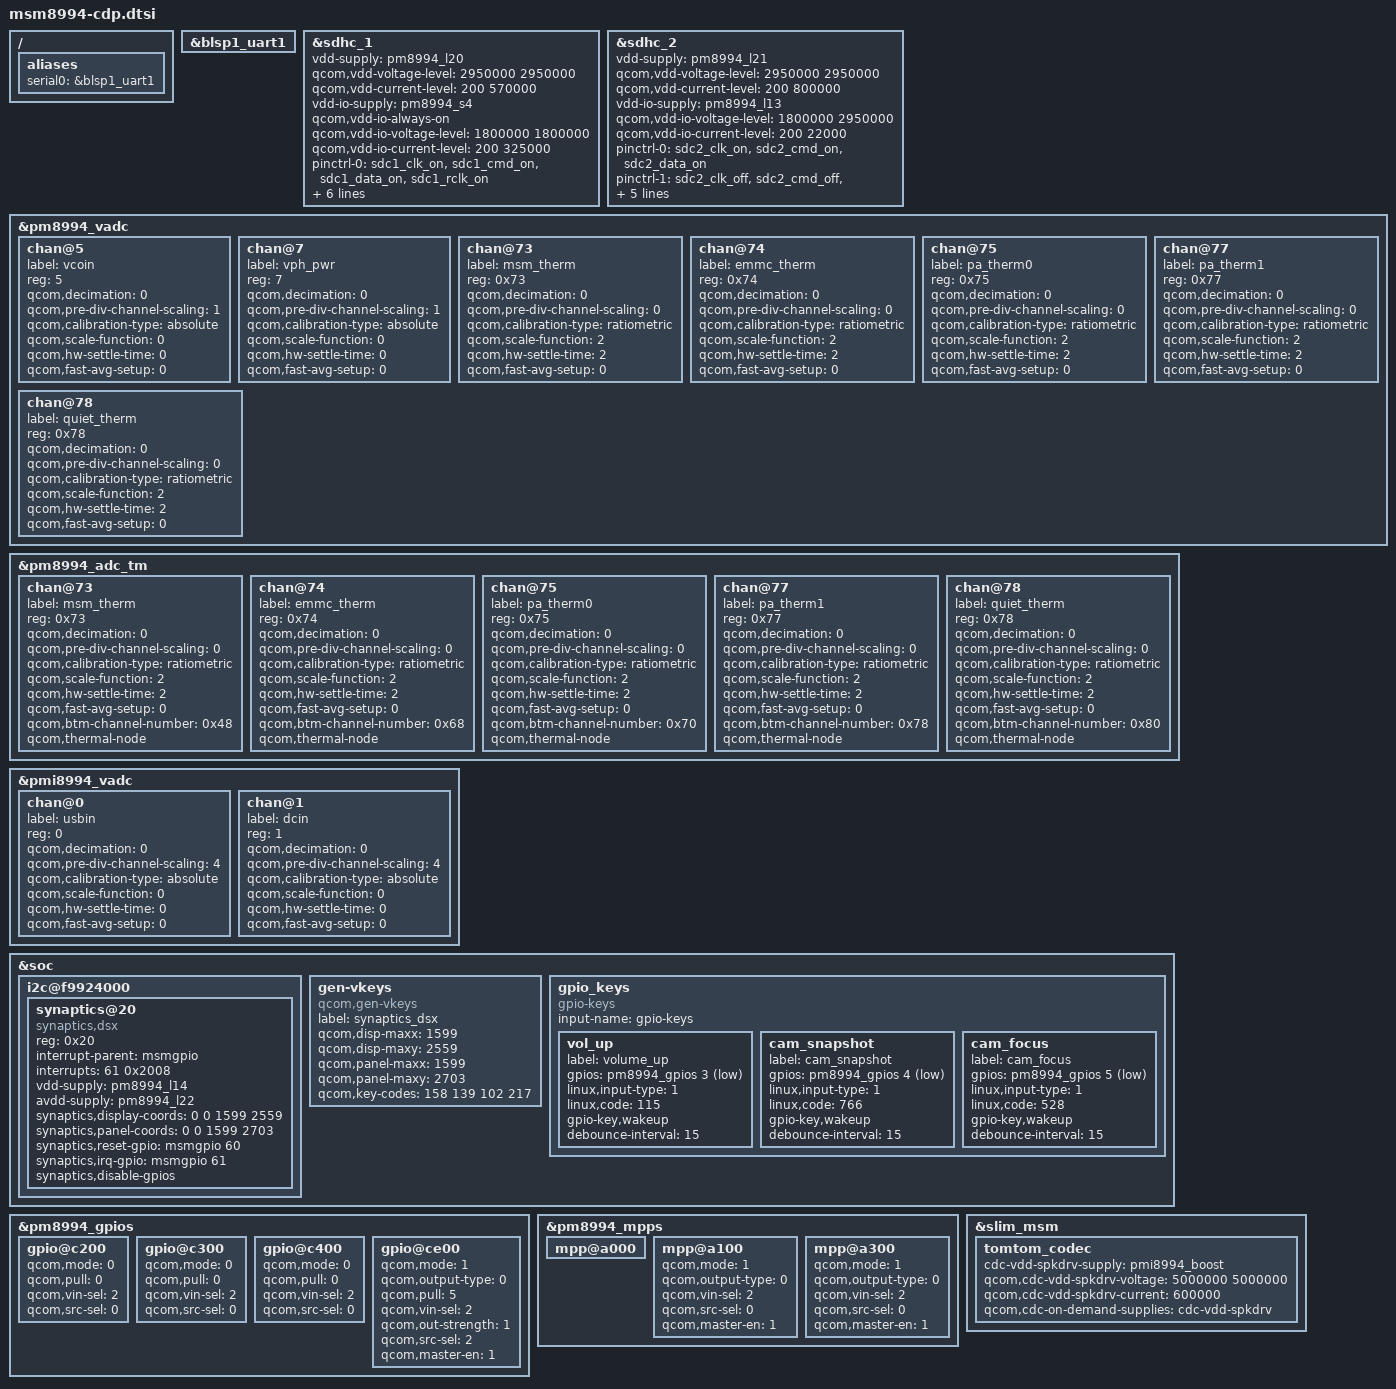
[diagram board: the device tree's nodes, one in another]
/* Copyright (c) 2014, The Linux Foundation. All rights reserved.
 *
 * This program is free software; you can redistribute it and/or modify
 * it under the terms of the GNU General Public License version 2 and
 * only version 2 as published by the Free Software Foundation.
 *
 * This program is distributed in the hope that it will be useful,
 * but WITHOUT ANY WARRANTY; without even the implied warranty of
 * MERCHANTABILITY or FITNESS FOR A PARTICULAR PURPOSE.  See the
 * GNU General Public License for more details.
 */

/ {
	aliases {
		serial0 = &blsp1_uart1;
	};
};

&blsp1_uart1{
	status = "ok";
};

&sdhc_1 {
	vdd-supply = <&pm8994_l20>;
	qcom,vdd-voltage-level = <2950000 2950000>;
	qcom,vdd-current-level = <200 570000>;

	vdd-io-supply = <&pm8994_s4>;
	qcom,vdd-io-always-on;
	qcom,vdd-io-voltage-level = <1800000 1800000>;
	qcom,vdd-io-current-level = <200 325000>;

	pinctrl-names = "active", "sleep";
	pinctrl-0 = <&sdc1_clk_on &sdc1_cmd_on &sdc1_data_on &sdc1_rclk_on>;
	pinctrl-1 = <&sdc1_clk_off &sdc1_cmd_off &sdc1_data_off &sdc1_rclk_off>;

	qcom,nonremovable;

	qcom,clk-rates = <400000 20000000 25000000 50000000 100000000 192000000>;
	qcom,bus-speed-mode = "HS200_1p8v", "DDR_1p8v";
	status = "ok";
};

&sdhc_2 {
	vdd-supply = <&pm8994_l21>;
	qcom,vdd-voltage-level = <2950000 2950000>;
	qcom,vdd-current-level = <200 800000>;

	vdd-io-supply = <&pm8994_l13>;
	qcom,vdd-io-voltage-level = <1800000 2950000>;
	qcom,vdd-io-current-level = <200 22000>;

	pinctrl-names = "active", "sleep";
	pinctrl-0 = <&sdc2_clk_on &sdc2_cmd_on &sdc2_data_on>;
	pinctrl-1 = <&sdc2_clk_off &sdc2_cmd_off &sdc2_data_off>;

	qcom,clk-rates = <400000 20000000 25000000 50000000 100000000 200000000>;
	qcom,bus-speed-mode = "SDR12", "SDR25", "SDR50", "DDR50", "SDR104";
	status = "ok";
};

&pm8994_vadc {
	chan@5 {
		label = "vcoin";
		reg = <5>;
		qcom,decimation = <0>;
		qcom,pre-div-channel-scaling = <1>;
		qcom,calibration-type = "absolute";
		qcom,scale-function = <0>;
		qcom,hw-settle-time = <0>;
		qcom,fast-avg-setup = <0>;
	};

	chan@7 {
		label = "vph_pwr";
		reg = <7>;
		qcom,decimation = <0>;
		qcom,pre-div-channel-scaling = <1>;
		qcom,calibration-type = "absolute";
		qcom,scale-function = <0>;
		qcom,hw-settle-time = <0>;
		qcom,fast-avg-setup = <0>;
	};

	chan@73 {
		label = "msm_therm";
		reg = <0x73>;
		qcom,decimation = <0>;
		qcom,pre-div-channel-scaling = <0>;
		qcom,calibration-type = "ratiometric";
		qcom,scale-function = <2>;
		qcom,hw-settle-time = <2>;
		qcom,fast-avg-setup = <0>;
	};

	chan@74 {
		label = "emmc_therm";
		reg = <0x74>;
		qcom,decimation = <0>;
		qcom,pre-div-channel-scaling = <0>;
		qcom,calibration-type = "ratiometric";
		qcom,scale-function = <2>;
		qcom,hw-settle-time = <2>;
		qcom,fast-avg-setup = <0>;
	};

	chan@75 {
		label = "pa_therm0";
		reg = <0x75>;
		qcom,decimation = <0>;
		qcom,pre-div-channel-scaling = <0>;
		qcom,calibration-type = "ratiometric";
		qcom,scale-function = <2>;
		qcom,hw-settle-time = <2>;
		qcom,fast-avg-setup = <0>;
	};

	chan@77 {
		label = "pa_therm1";
		reg = <0x77>;
		qcom,decimation = <0>;
		qcom,pre-div-channel-scaling = <0>;
		qcom,calibration-type = "ratiometric";
		qcom,scale-function = <2>;
		qcom,hw-settle-time = <2>;
		qcom,fast-avg-setup = <0>;
	};

	chan@78 {
		label = "quiet_therm";
		reg = <0x78>;
		qcom,decimation = <0>;
		qcom,pre-div-channel-scaling = <0>;
		qcom,calibration-type = "ratiometric";
		qcom,scale-function = <2>;
		qcom,hw-settle-time = <2>;
		qcom,fast-avg-setup = <0>;
	};
};

&pm8994_adc_tm {
	chan@73 {
		label = "msm_therm";
		reg = <0x73>;
		qcom,decimation = <0>;
		qcom,pre-div-channel-scaling = <0>;
		qcom,calibration-type = "ratiometric";
		qcom,scale-function = <2>;
		qcom,hw-settle-time = <2>;
		qcom,fast-avg-setup = <0>;
		qcom,btm-channel-number = <0x48>;
		qcom,thermal-node;
	};

	chan@74 {
		label = "emmc_therm";
		reg = <0x74>;
		qcom,decimation = <0>;
		qcom,pre-div-channel-scaling = <0>;
		qcom,calibration-type = "ratiometric";
		qcom,scale-function = <2>;
		qcom,hw-settle-time = <2>;
		qcom,fast-avg-setup = <0>;
		qcom,btm-channel-number = <0x68>;
		qcom,thermal-node;
	};

	chan@75 {
		label = "pa_therm0";
		reg = <0x75>;
		qcom,decimation = <0>;
		qcom,pre-div-channel-scaling = <0>;
		qcom,calibration-type = "ratiometric";
		qcom,scale-function = <2>;
		qcom,hw-settle-time = <2>;
		qcom,fast-avg-setup = <0>;
		qcom,btm-channel-number = <0x70>;
		qcom,thermal-node;
	};

	chan@77 {
		label = "pa_therm1";
		reg = <0x77>;
		qcom,decimation = <0>;
		qcom,pre-div-channel-scaling = <0>;
		qcom,calibration-type = "ratiometric";
		qcom,scale-function = <2>;
		qcom,hw-settle-time = <2>;
		qcom,fast-avg-setup = <0>;
		qcom,btm-channel-number = <0x78>;
		qcom,thermal-node;
	};

	chan@78 {
		label = "quiet_therm";
		reg = <0x78>;
		qcom,decimation = <0>;
		qcom,pre-div-channel-scaling = <0>;
		qcom,calibration-type = "ratiometric";
		qcom,scale-function = <2>;
		qcom,hw-settle-time = <2>;
		qcom,fast-avg-setup = <0>;
		qcom,btm-channel-number = <0x80>;
		qcom,thermal-node;
	};
};

&pmi8994_vadc {
	chan@0 {
		label = "usbin";
		reg = <0>;
		qcom,decimation = <0>;
		qcom,pre-div-channel-scaling = <4>;
		qcom,calibration-type = "absolute";
		qcom,scale-function = <0>;
		qcom,hw-settle-time = <0>;
		qcom,fast-avg-setup = <0>;
	};

	chan@1 {
		label = "dcin";
		reg = <1>;
		qcom,decimation = <0>;
		qcom,pre-div-channel-scaling = <4>;
		qcom,calibration-type = "absolute";
		qcom,scale-function = <0>;
		qcom,hw-settle-time = <0>;
		qcom,fast-avg-setup = <0>;
	};
};

&soc {
	i2c@f9924000 {
		synaptics@20 {
			compatible = "synaptics,dsx";
			reg = <0x20>;
			interrupt-parent = <&msmgpio>;
			interrupts = <61 0x2008>;
			vdd-supply = <&pm8994_l14>;
			avdd-supply = <&pm8994_l22>;
			synaptics,display-coords = <0 0 1599 2559>;
			synaptics,panel-coords = <0 0 1599 2703>;
			synaptics,reset-gpio = <&msmgpio 60 0x00>;
			synaptics,irq-gpio = <&msmgpio 61 0x2008>;
			synaptics,disable-gpios;
		};
	};

	gen-vkeys {
		compatible = "qcom,gen-vkeys";
		label = "synaptics_dsx";
		qcom,disp-maxx = <1599>;
		qcom,disp-maxy = <2559>;
		qcom,panel-maxx = <1599>;
		qcom,panel-maxy = <2703>;
		qcom,key-codes = <158 139 102 217>;
	};

	gpio_keys {
		compatible = "gpio-keys";
		input-name = "gpio-keys";

		vol_up {
			label = "volume_up";
			gpios = <&pm8994_gpios 3 0x1>;
			linux,input-type = <1>;
			linux,code = <115>;
			gpio-key,wakeup;
			debounce-interval = <15>;
		};

		cam_snapshot {
			label = "cam_snapshot";
			gpios = <&pm8994_gpios 4 0x1>;
			linux,input-type = <1>;
			linux,code = <766>;
			gpio-key,wakeup;
			debounce-interval = <15>;
		};

		cam_focus {
			label = "cam_focus";
			gpios = <&pm8994_gpios 5 0x1>;
			linux,input-type = <1>;
			linux,code = <528>;
			gpio-key,wakeup;
			debounce-interval = <15>;
		};


	};
};

&pm8994_gpios {
	gpio@c200 { /* GPIO 3 */
		qcom,mode = <0>;
		qcom,pull = <0>;
		qcom,vin-sel = <2>;
		qcom,src-sel = <0>;
	};

	gpio@c300 { /* GPIO 4 */
		qcom,mode = <0>;
		qcom,pull = <0>;
		qcom,vin-sel = <2>;
		qcom,src-sel = <0>;
	};

	gpio@c400 { /* GPIO 5 */
		qcom,mode = <0>;
		qcom,pull = <0>;
		qcom,vin-sel = <2>;
		qcom,src-sel = <0>;
	};

	gpio@ce00 { /* GPIO 15 */
		qcom,mode = <1>;
		qcom,output-type = <0>;
		qcom,pull = <5>;
		qcom,vin-sel = <2>;
		qcom,out-strength = <1>;
		qcom,src-sel = <2>;
		qcom,master-en = <1>;
	};
};

&pm8994_mpps {
	mpp@a000 { /* MPP 1 */
	};

	mpp@a100 { /* MPP 2 */
		qcom,mode = <1>;		/* Digital output */
		qcom,output-type = <0>;		/* CMOS logic */
		qcom,vin-sel = <2>;		/* S4 1.8V */
		qcom,src-sel = <0>;		/* Constant */
		qcom,master-en = <1>;		/* Enable GPIO */
	};

	mpp@a300 { /* MPP 4 */
		/* HDMI_5v_vreg regulator enable */
		qcom,mode = <1>;		/* Digital output */
		qcom,output-type = <0>;		/* CMOS logic */
		qcom,vin-sel = <2>;		/* S4 1.8V */
		qcom,src-sel = <0>;		/* Constant */
		qcom,master-en = <1>;		/* Enable GPIO */
	};
};

&slim_msm {
	tomtom_codec {
		cdc-vdd-spkdrv-supply = <&pmi8994_boost>;
		qcom,cdc-vdd-spkdrv-voltage = <5000000 5000000>;
		qcom,cdc-vdd-spkdrv-current = <600000>;
		qcom,cdc-on-demand-supplies = "cdc-vdd-spkdrv";
	};
};
